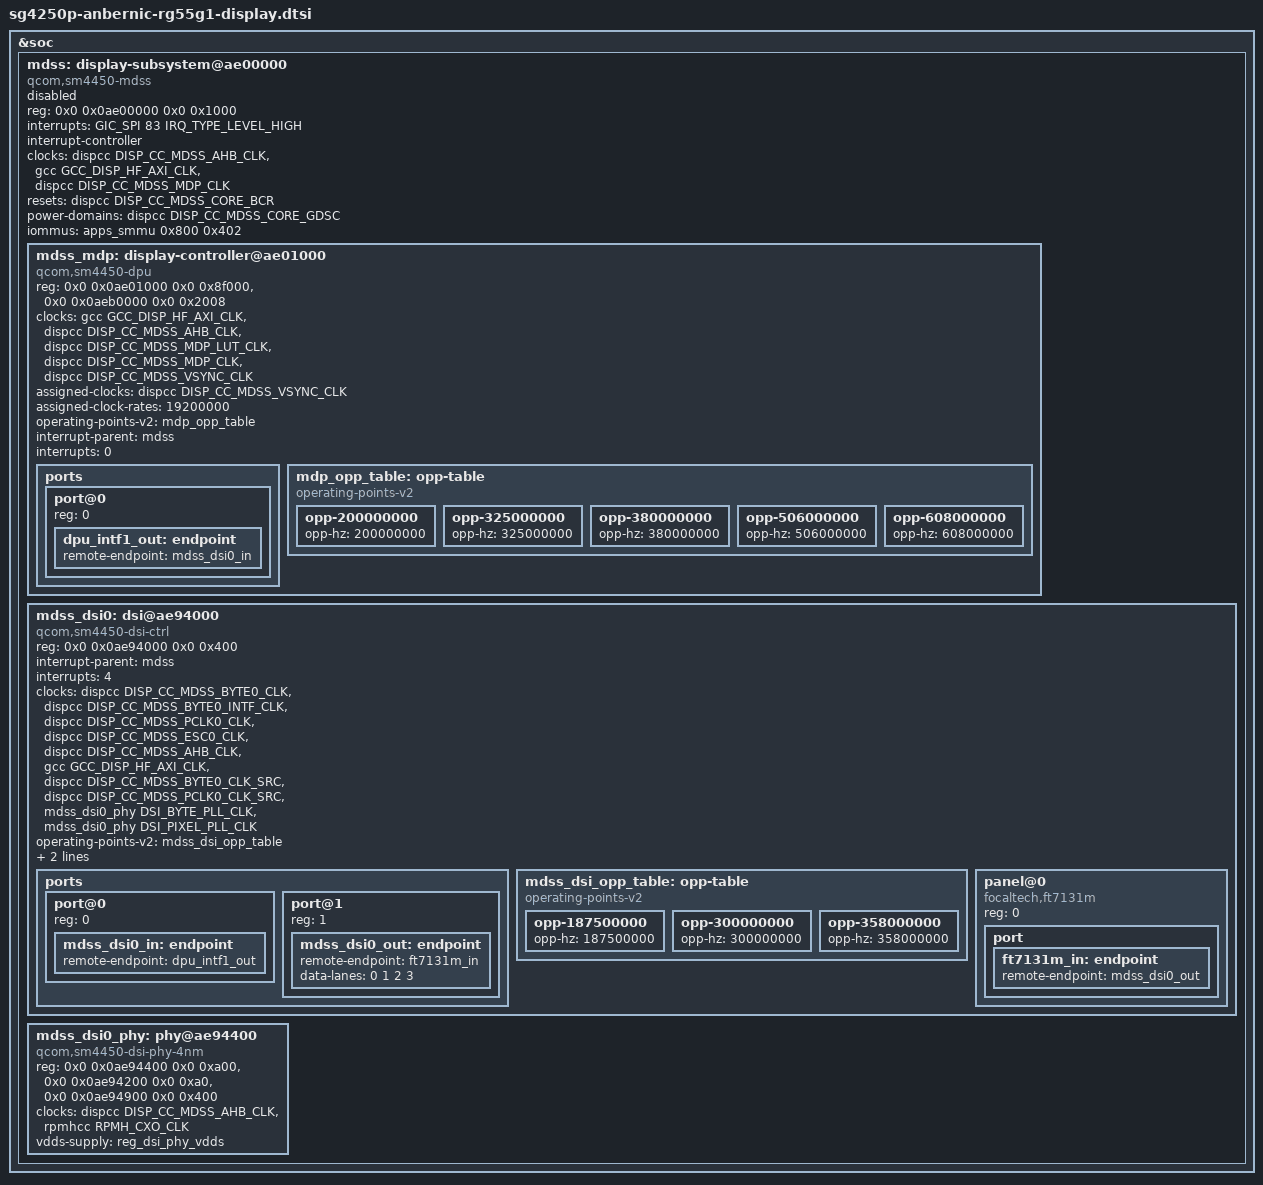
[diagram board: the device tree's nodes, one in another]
// SPDX-License-Identifier: GPL-2.0-only
/*
 * RG55G1 MSM display (SM4450 DPU + FT7131M DSI panel).
 * Mainline labels against sm4450.dtsi / board DTS.
 */
#include <dt-bindings/clock/qcom,dsi-phy-28nm.h>
#include <dt-bindings/gpio/gpio.h>

&soc {
	mdss: display-subsystem@ae00000 {
		compatible = "qcom,sm4450-mdss";
		reg = <0x0 0x0ae00000 0x0 0x1000>;
		reg-names = "mdss";

		interrupts = <GIC_SPI 83 IRQ_TYPE_LEVEL_HIGH>;
		interrupt-controller;
		#interrupt-cells = <1>;

		clocks = <&dispcc DISP_CC_MDSS_AHB_CLK>,
			 <&gcc GCC_DISP_HF_AXI_CLK>,
			 <&dispcc DISP_CC_MDSS_MDP_CLK>;
		clock-names = "iface", "bus", "core";

		resets = <&dispcc DISP_CC_MDSS_CORE_BCR>;
		power-domains = <&dispcc DISP_CC_MDSS_CORE_GDSC>;

		/* ROCKNIX: MDSS SID 0x800 — clean KMS after INTF quiesce. */
		iommus = <&apps_smmu 0x800 0x402>;

		#address-cells = <2>;
		#size-cells = <2>;
		ranges;

		status = "disabled";

		mdss_mdp: display-controller@ae01000 {
			compatible = "qcom,sm4450-dpu";
			reg = <0x0 0x0ae01000 0x0 0x8f000>,
			      <0x0 0x0aeb0000 0x0 0x2008>;
			reg-names = "mdp", "vbif";

			clocks = <&gcc GCC_DISP_HF_AXI_CLK>,
				 <&dispcc DISP_CC_MDSS_AHB_CLK>,
				 <&dispcc DISP_CC_MDSS_MDP_LUT_CLK>,
				 <&dispcc DISP_CC_MDSS_MDP_CLK>,
				 <&dispcc DISP_CC_MDSS_VSYNC_CLK>;
			clock-names = "bus",
				      "iface",
				      "lut",
				      "core",
				      "vsync";

			assigned-clocks = <&dispcc DISP_CC_MDSS_VSYNC_CLK>;
			assigned-clock-rates = <19200000>;

			operating-points-v2 = <&mdp_opp_table>;
			/* CX already on from ABL; rpmhpd vote times out on this board. */

			interrupt-parent = <&mdss>;
			interrupts = <0>;

			ports {
				#address-cells = <1>;
				#size-cells = <0>;

				port@0 {
					reg = <0>;
					dpu_intf1_out: endpoint {
						remote-endpoint = <&mdss_dsi0_in>;
					};
				};
			};

			mdp_opp_table: opp-table {
				compatible = "operating-points-v2";

				/* No required-opps — rpmhpd votes time out on RG55G1. */
				opp-200000000 {
					opp-hz = /bits/ 64 <200000000>;
				};

				opp-325000000 {
					opp-hz = /bits/ 64 <325000000>;
				};

				opp-380000000 {
					opp-hz = /bits/ 64 <380000000>;
				};

				opp-506000000 {
					opp-hz = /bits/ 64 <506000000>;
				};

				opp-608000000 {
					opp-hz = /bits/ 64 <608000000>;
				};
			};
		};

		mdss_dsi0: dsi@ae94000 {
			compatible = "qcom,sm4450-dsi-ctrl", "qcom,mdss-dsi-ctrl";
			reg = <0x0 0x0ae94000 0x0 0x400>;
			reg-names = "dsi_ctrl";

			interrupt-parent = <&mdss>;
			interrupts = <4>;

			/*
			 * SM4450 uses 6G v2.9 ops (runtime BYTE/PCLK reparent
			 * after phy_enable). Needs *_src + dsi_pll_* clocks —
			 * assigned-clock-parents alone is not enough.
			 */
			clocks = <&dispcc DISP_CC_MDSS_BYTE0_CLK>,
				 <&dispcc DISP_CC_MDSS_BYTE0_INTF_CLK>,
				 <&dispcc DISP_CC_MDSS_PCLK0_CLK>,
				 <&dispcc DISP_CC_MDSS_ESC0_CLK>,
				 <&dispcc DISP_CC_MDSS_AHB_CLK>,
				 <&gcc GCC_DISP_HF_AXI_CLK>,
				 <&dispcc DISP_CC_MDSS_BYTE0_CLK_SRC>,
				 <&dispcc DISP_CC_MDSS_PCLK0_CLK_SRC>,
				 <&mdss_dsi0_phy DSI_BYTE_PLL_CLK>,
				 <&mdss_dsi0_phy DSI_PIXEL_PLL_CLK>;
			clock-names = "byte",
				      "byte_intf",
				      "pixel",
				      "core",
				      "iface",
				      "bus",
				      "byte_src",
				      "pixel_src",
				      "dsi_pll_byte",
				      "dsi_pll_pixel";

			operating-points-v2 = <&mdss_dsi_opp_table>;
			/* CX already on; rpmhpd vote times out on this board. */

			phys = <&mdss_dsi0_phy>;
			phy-names = "dsi";

			vdda-supply = <&reg_dsi_vdda>;

			#address-cells = <1>;
			#size-cells = <0>;

			ports {
				#address-cells = <1>;
				#size-cells = <0>;

				port@0 {
					reg = <0>;
					mdss_dsi0_in: endpoint {
						remote-endpoint = <&dpu_intf1_out>;
					};
				};

				port@1 {
					reg = <1>;
					mdss_dsi0_out: endpoint {
						remote-endpoint = <&ft7131m_in>;
						data-lanes = <0 1 2 3>;
					};
				};
			};

			mdss_dsi_opp_table: opp-table {
				compatible = "operating-points-v2";

				/* No required-opps — rpmhpd votes time out on RG55G1. */
				opp-187500000 {
					opp-hz = /bits/ 64 <187500000>;
				};

				opp-300000000 {
					opp-hz = /bits/ 64 <300000000>;
				};

				opp-358000000 {
					opp-hz = /bits/ 64 <358000000>;
				};
			};

			panel@0 {
				compatible = "focaltech,ft7131m";
				reg = <0>;

				port {
					ft7131m_in: endpoint {
						remote-endpoint = <&mdss_dsi0_out>;
					};
				};
			};
		};

		mdss_dsi0_phy: phy@ae94400 {
			compatible = "qcom,sm4450-dsi-phy-4nm",
				     "qcom,ravelin-dsi-phy-4nm";
			/* Stock Ravelin: phy @ae94400, lanes @ae94200, pll @ae94900 */
			reg = <0x0 0x0ae94400 0x0 0xa00>,
			      <0x0 0x0ae94200 0x0 0xa0>,
			      <0x0 0x0ae94900 0x0 0x400>;
			reg-names = "dsi_phy",
				    "dsi_phy_lane",
				    "dsi_pll";

			#clock-cells = <1>;
			#phy-cells = <0>;

			clocks = <&dispcc DISP_CC_MDSS_AHB_CLK>,
				 <&rpmhcc RPMH_CXO_CLK>;
			clock-names = "iface", "ref";

			vdds-supply = <&reg_dsi_phy_vdds>;
		};
	};
};
